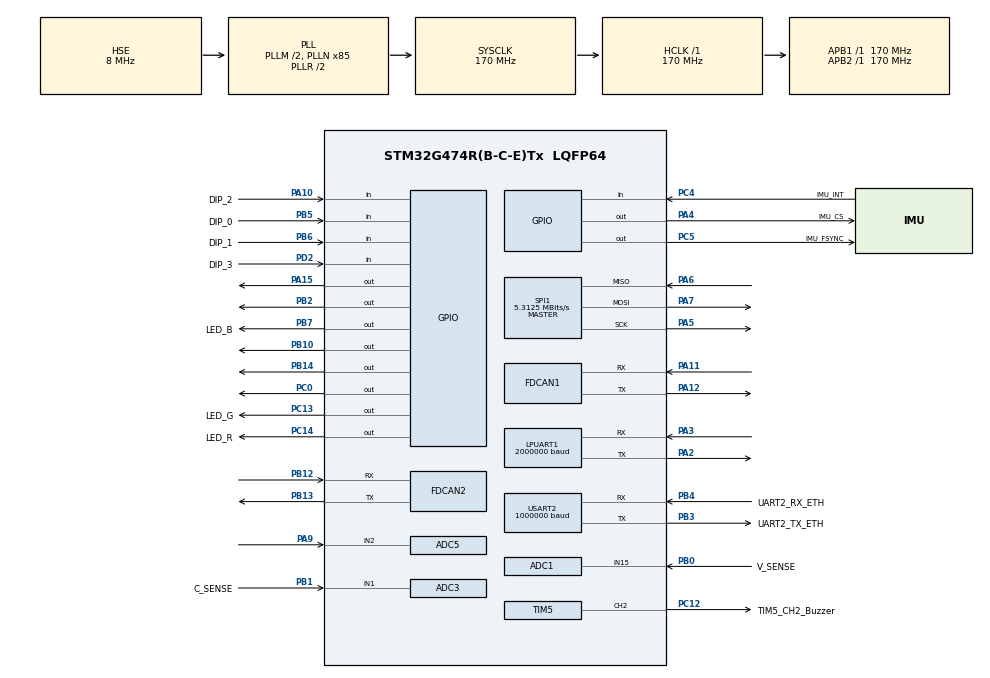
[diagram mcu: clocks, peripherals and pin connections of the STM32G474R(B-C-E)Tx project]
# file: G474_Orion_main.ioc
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ADC1.Channel-0\#ChannelRegularConversion=ADC_CHANNEL_15
ADC1.ContinuousConvMode=ENABLE
ADC1.DMAContinuousRequests=ENABLE
ADC1.NbrOfConversionFlag=1
ADC1.OffsetNumber-0\#ChannelRegularConversion=ADC_OFFSET_NONE
ADC1.OversamplingMode=ENABLE
ADC1.Rank-0\#ChannelRegularConversion=1
ADC1.Ratio=ADC_OVERSAMPLING_RATIO_4
ADC1.RightBitShift=ADC_RIGHTBITSHIFT_2
ADC1.SamplingTime-0\#ChannelRegularConversion=ADC_SAMPLETIME_640CYCLES_5
ADC1.master=1
ADC3.Channel-0\#ChannelRegularConversion=ADC_CHANNEL_1
ADC3.ContinuousConvMode=ENABLE
ADC3.DMAContinuousRequests=ENABLE
ADC3.NbrOfConversion=1
ADC3.NbrOfConversionFlag=1
ADC3.OffsetNumber-0\#ChannelRegularConversion=ADC_OFFSET_NONE
ADC3.OversamplingMode=ENABLE
ADC3.Rank-0\#ChannelRegularConversion=1
ADC3.Ratio=ADC_OVERSAMPLING_RATIO_4
ADC3.RightBitShift=ADC_RIGHTBITSHIFT_2
ADC3.SamplingTime-0\#ChannelRegularConversion=ADC_SAMPLETIME_640CYCLES_5
ADC3.master=1
ADC5.Channel-1\#ChannelRegularConversion=ADC_CHANNEL_2
ADC5.ContinuousConvMode=ENABLE
ADC5.DMAContinuousRequests=ENABLE
ADC5.EOCSelection=ADC_EOC_SINGLE_CONV
ADC5.EnableRegularConversion=ENABLE
ADC5.NbrOfConversionFlag=1
ADC5.OffsetNumber-1\#ChannelRegularConversion=ADC_OFFSET_NONE
ADC5.OversamplingMode=ENABLE
ADC5.Rank-1\#ChannelRegularConversion=1
ADC5.Ratio=ADC_OVERSAMPLING_RATIO_4
ADC5.RightBitShift=ADC_RIGHTBITSHIFT_2
ADC5.SamplingTime-1\#ChannelRegularConversion=ADC_SAMPLETIME_640CYCLES_5
Dma.ADC1.2.Direction=DMA_PERIPH_TO_MEMORY
Dma.ADC1.2.EventEnable=DISABLE
Dma.ADC1.2.Instance=DMA1_Channel5
Dma.ADC1.2.MemDataAlignment=DMA_MDATAALIGN_HALFWORD
Dma.ADC1.2.MemInc=DMA_MINC_ENABLE
Dma.ADC1.2.Mode=DMA_CIRCULAR
Dma.ADC1.2.PeriphDataAlignment=DMA_PDATAALIGN_HALFWORD
Dma.ADC1.2.PeriphInc=DMA_PINC_DISABLE
Dma.ADC1.2.Polarity=HAL_DMAMUX_REQ_GEN_RISING
Dma.ADC1.2.Priority=DMA_PRIORITY_LOW
Dma.ADC1.2.RequestNumber=1
Dma.ADC1.2.SignalID=NONE
Dma.ADC1.2.SyncEnable=DISABLE
Dma.ADC1.2.SyncPolarity=HAL_DMAMUX_SYNC_NO_EVENT
Dma.ADC1.2.SyncRequestNumber=1
Dma.ADC1.2.SyncSignalID=NONE
Dma.ADC3.1.Direction=DMA_PERIPH_TO_MEMORY
Dma.ADC3.1.EventEnable=DISABLE
Dma.ADC3.1.Instance=DMA1_Channel3
Dma.ADC3.1.MemDataAlignment=DMA_MDATAALIGN_HALFWORD
Dma.ADC3.1.MemInc=DMA_MINC_ENABLE
Dma.ADC3.1.Mode=DMA_CIRCULAR
Dma.ADC3.1.PeriphDataAlignment=DMA_PDATAALIGN_HALFWORD
Dma.ADC3.1.PeriphInc=DMA_PINC_DISABLE
Dma.ADC3.1.Polarity=HAL_DMAMUX_REQ_GEN_RISING
Dma.ADC3.1.Priority=DMA_PRIORITY_LOW
Dma.ADC3.1.RequestNumber=1
Dma.ADC3.1.SignalID=NONE
Dma.ADC3.1.SyncEnable=DISABLE
Dma.ADC3.1.SyncPolarity=HAL_DMAMUX_SYNC_NO_EVENT
Dma.ADC3.1.SyncRequestNumber=1
Dma.ADC3.1.SyncSignalID=NONE
Dma.ADC5.0.Direction=DMA_PERIPH_TO_MEMORY
Dma.ADC5.0.EventEnable=DISABLE
Dma.ADC5.0.Instance=DMA1_Channel4
Dma.ADC5.0.MemDataAlignment=DMA_MDATAALIGN_HALFWORD
Dma.ADC5.0.MemInc=DMA_MINC_ENABLE
Dma.ADC5.0.Mode=DMA_CIRCULAR
Dma.ADC5.0.PeriphDataAlignment=DMA_PDATAALIGN_HALFWORD
Dma.ADC5.0.PeriphInc=DMA_PINC_DISABLE
Dma.ADC5.0.Polarity=HAL_DMAMUX_REQ_GEN_RISING
Dma.ADC5.0.Priority=DMA_PRIORITY_LOW
Dma.ADC5.0.RequestNumber=1
Dma.ADC5.0.SignalID=NONE
Dma.ADC5.0.SyncEnable=DISABLE
Dma.ADC5.0.SyncPolarity=HAL_DMAMUX_SYNC_NO_EVENT
Dma.ADC5.0.SyncRequestNumber=1
Dma.ADC5.0.SyncSignalID=NONE
Dma.LPUART1_RX.3.Direction=DMA_PERIPH_TO_MEMORY
Dma.LPUART1_RX.3.EventEnable=DISABLE
Dma.LPUART1_RX.3.Instance=DMA1_Channel6
Dma.LPUART1_RX.3.MemDataAlignment=DMA_MDATAALIGN_BYTE
Dma.LPUART1_RX.3.MemInc=DMA_MINC_ENABLE
Dma.LPUART1_RX.3.Mode=DMA_CIRCULAR
Dma.LPUART1_RX.3.PeriphDataAlignment=DMA_PDATAALIGN_BYTE
Dma.LPUART1_RX.3.PeriphInc=DMA_PINC_DISABLE
Dma.LPUART1_RX.3.Polarity=HAL_DMAMUX_REQ_GEN_RISING
Dma.LPUART1_RX.3.Priority=DMA_PRIORITY_LOW
Dma.LPUART1_RX.3.RequestNumber=1
Dma.LPUART1_RX.3.SignalID=NONE
Dma.LPUART1_RX.3.SyncEnable=DISABLE
Dma.LPUART1_RX.3.SyncPolarity=HAL_DMAMUX_SYNC_NO_EVENT
Dma.LPUART1_RX.3.SyncRequestNumber=1
Dma.LPUART1_RX.3.SyncSignalID=NONE
Dma.LPUART1_TX.4.Direction=DMA_MEMORY_TO_PERIPH
Dma.LPUART1_TX.4.EventEnable=DISABLE
Dma.LPUART1_TX.4.Instance=DMA1_Channel7
Dma.LPUART1_TX.4.MemDataAlignment=DMA_MDATAALIGN_BYTE
Dma.LPUART1_TX.4.MemInc=DMA_MINC_ENABLE
Dma.LPUART1_TX.4.Mode=DMA_NORMAL
Dma.LPUART1_TX.4.PeriphDataAlignment=DMA_PDATAALIGN_BYTE
Dma.LPUART1_TX.4.PeriphInc=DMA_PINC_DISABLE
Dma.LPUART1_TX.4.Polarity=HAL_DMAMUX_REQ_GEN_RISING
Dma.LPUART1_TX.4.Priority=DMA_PRIORITY_LOW
Dma.LPUART1_TX.4.RequestNumber=1
Dma.LPUART1_TX.4.SignalID=NONE
Dma.LPUART1_TX.4.SyncEnable=DISABLE
Dma.LPUART1_TX.4.SyncPolarity=HAL_DMAMUX_SYNC_NO_EVENT
Dma.LPUART1_TX.4.SyncRequestNumber=1
Dma.LPUART1_TX.4.SyncSignalID=NONE
Dma.Request0=ADC5
Dma.Request1=ADC3
Dma.Request2=ADC1
Dma.Request3=LPUART1_RX
Dma.Request4=LPUART1_TX
Dma.Request5=USART2_TX
Dma.USART2_TX.5.Direction=DMA_MEMORY_TO_PERIPH
Dma.USART2_TX.5.EventEnable=DISABLE
Dma.USART2_TX.5.Instance=DMA1_Channel8
Dma.USART2_TX.5.MemDataAlignment=DMA_MDATAALIGN_BYTE
Dma.USART2_TX.5.MemInc=DMA_MINC_ENABLE
Dma.USART2_TX.5.Mode=DMA_NORMAL
Dma.USART2_TX.5.PeriphDataAlignment=DMA_PDATAALIGN_BYTE
Dma.USART2_TX.5.PeriphInc=DMA_PINC_DISABLE
Dma.USART2_TX.5.Polarity=HAL_DMAMUX_REQ_GEN_RISING
Dma.USART2_TX.5.Priority=DMA_PRIORITY_LOW
Dma.USART2_TX.5.RequestNumber=1
Dma.USART2_TX.5.SignalID=NONE
Dma.USART2_TX.5.SyncEnable=DISABLE
Dma.USART2_TX.5.SyncPolarity=HAL_DMAMUX_SYNC_NO_EVENT
Dma.USART2_TX.5.SyncRequestNumber=1
Dma.USART2_TX.5.SyncSignalID=NONE
FDCAN1.AutoRetransmission=ENABLE
FDCAN1.CalculateBaudRateNominal=999999
FDCAN1.CalculateTimeBitNominal=1000
FDCAN1.CalculateTimeQuantumNominal=58.82352941176471
FDCAN1.DataPrescaler=10
FDCAN1.DataTimeSeg1=12
FDCAN1.DataTimeSeg2=2
FDCAN1.NominalPrescaler=10
FDCAN1.NominalTimeSeg1=14
FDCAN1.NominalTimeSeg2=2
FDCAN2.AutoRetransmission=ENABLE
FDCAN2.CalculateBaudRateNominal=999999
FDCAN2.CalculateTimeBitNominal=1000
FDCAN2.CalculateTimeQuantumNominal=58.82352941176471
FDCAN2.DataPrescaler=10
FDCAN2.DataTimeSeg1=12
FDCAN2.DataTimeSeg2=2
FDCAN2.NominalPrescaler=10
FDCAN2.NominalTimeSeg1=14
FDCAN2.NominalTimeSeg2=2
LPUART1.BaudRate=2000000
LPUART1.DMADisableonRxErrorParam=UART_ADVFEATURE_DMA_DISABLEONRXERROR
LPUART1.OverrunDisableParam=UART_ADVFEATURE_OVERRUN_ENABLE
Mcu.Family=STM32G4
Mcu.Name=STM32G474R(B-C-E)Tx
Mcu.Package=LQFP64
NVIC.DMA1_Channel3_IRQn=true\:9\:0\:true\:false\:true\:false\:true\:true
NVIC.DMA1_Channel4_IRQn=true\:10\:0\:true\:false\:true\:false\:true\:true
NVIC.DMA1_Channel5_IRQn=true\:11\:0\:true\:false\:true\:false\:true\:true
NVIC.DMA1_Channel6_IRQn=true\:14\:0\:true\:false\:true\:false\:true\:true
NVIC.DMA1_Channel7_IRQn=true\:15\:0\:true\:false\:true\:false\:true\:true
NVIC.DMA1_Channel8_IRQn=true\:0\:0\:false\:false\:true\:false\:true\:true
NVIC.FDCAN1_IT0_IRQn=true\:3\:0\:true\:false\:true\:true\:true\:true
NVIC.FDCAN1_IT1_IRQn=true\:4\:0\:true\:false\:true\:true\:true\:true
NVIC.FDCAN2_IT0_IRQn=true\:6\:0\:true\:false\:true\:true\:true\:true
NVIC.FDCAN2_IT1_IRQn=true\:7\:0\:true\:false\:true\:true\:true\:true
NVIC.LPUART1_IRQn=true\:13\:0\:true\:false\:true\:true\:true\:true
NVIC.PriorityGroup=NVIC_PRIORITYGROUP_4
NVIC.TIM7_DAC_IRQn=true\:8\:0\:true\:false\:true\:true\:true\:true
NVIC.USART2_IRQn=true\:1\:0\:true\:false\:true\:true\:true\:true
PA10.GPIO_Label=DIP_2
PA10.Signal=GPIO_Input
PA11.Mode=FDCAN_Activate
PA11.Signal=FDCAN1_RX
PA12.Mode=FDCAN_Activate
PA12.Signal=FDCAN1_TX
PA13.Mode=Serial_Wire
PA13.Signal=SYS_JTMS-SWDIO
PA14.Mode=Serial_Wire
PA14.Signal=SYS_JTCK-SWCLK
PA15.Signal=GPIO_Output
PA2.GPIO_PuPd=GPIO_PULLUP
PA2.GPIO_Speed=GPIO_SPEED_FREQ_MEDIUM
PA2.Mode=Asynchronous
PA2.Signal=LPUART1_TX
PA3.GPIO_PuPd=GPIO_PULLUP
PA3.GPIO_Speed=GPIO_SPEED_FREQ_MEDIUM
PA3.Mode=Asynchronous
PA3.Signal=LPUART1_RX
PA4.GPIO_Label=IMU_CS
PA4.Signal=GPIO_Output
PA5.Mode=Full_Duplex_Master
PA5.Signal=SPI1_SCK
PA6.Mode=Full_Duplex_Master
PA6.Signal=SPI1_MISO
PA7.Mode=Full_Duplex_Master
PA7.Signal=SPI1_MOSI
PA9.Mode=IN2-Single-Ended
PA9.Signal=ADC5_IN2
PB0.GPIO_Label=V_SENSE
PB0.Mode=IN15-Single-Ended
PB0.Signal=ADC1_IN15
PB1.GPIO_Label=C_SENSE
PB1.Mode=IN1-Single-Ended
PB1.Signal=ADC3_IN1
PB10.Signal=GPIO_Output
PB12.Mode=FDCAN_Activate
PB12.Signal=FDCAN2_RX
PB13.Mode=FDCAN_Activate
PB13.Signal=FDCAN2_TX
PB14.Signal=GPIO_Output
PB2.Signal=GPIO_Output
PB3.GPIO_Label=UART2_TX_ETH
PB3.GPIO_Speed=GPIO_SPEED_FREQ_MEDIUM
PB3.Mode=Asynchronous
PB3.Signal=USART2_TX
PB4.GPIO_Label=UART2_RX_ETH
PB4.GPIO_PuPd=GPIO_PULLUP
PB4.GPIO_Speed=GPIO_SPEED_FREQ_MEDIUM
PB4.Mode=Asynchronous
PB4.Signal=USART2_RX
PB5.GPIO_Label=DIP_0
PB5.Signal=GPIO_Input
PB6.GPIO_Label=DIP_1
PB6.Signal=GPIO_Input
PB7.GPIO_Label=LED_B
PB7.Signal=GPIO_Output
PC0.Signal=GPIO_Output
PC12.GPIO_Label=TIM5_CH2_Buzzer
PC12.Signal=S_TIM5_CH2
PC13.GPIO_Label=LED_G
PC13.Signal=GPIO_Output
PC14-OSC32_IN.GPIO_Label=LED_R
PC14-OSC32_IN.Signal=GPIO_Output
PC4.GPIO_Label=IMU_INT
PC4.Signal=GPIO_Input
PC5.GPIO_Label=IMU_FSYNC
PC5.Signal=GPIO_Output
PD2.GPIO_Label=DIP_3
PD2.Signal=GPIO_Input
PF0-OSC_IN.Mode=HSE-External-Oscillator
PF0-OSC_IN.Signal=RCC_OSC_IN
PF1-OSC_OUT.Mode=HSE-External-Oscillator
PF1-OSC_OUT.Signal=RCC_OSC_OUT
ProjectManager.HeapSize=0x200
ProjectManager.StackSize=0x400
ProjectManager.TargetToolchain=STM32CubeIDE
RCC.ADC12Freq_Value=170000000
RCC.ADC345Freq_Value=170000000
RCC.AHBFreq_Value=170000000
RCC.APB1Freq_Value=170000000
RCC.APB1TimFreq_Value=170000000
RCC.APB2Freq_Value=170000000
RCC.APB2TimFreq_Value=170000000
RCC.CortexFreq_Value=170000000
RCC.EXTERNAL_CLOCK_VALUE=12288000
RCC.HCLKFreq_Value=170000000
RCC.HSE_VALUE=8000000
RCC.HSI48_VALUE=48000000
RCC.HSI_VALUE=16000000
RCC.LSE_VALUE=32768
RCC.PLLM=RCC_PLLM_DIV2
RCC.PLLN=85
RCC.PLLSourceVirtual=RCC_PLLSOURCE_HSE
RCC.SYSCLKFreq_VALUE=170000000
RCC.SYSCLKSource=RCC_SYSCLKSOURCE_PLLCLK
RCC.USBFreq_Value=170000000
RCC.VCOOutputFreq_Value=340000000
SH.S_TIM5_CH2.0=TIM5_CH2,PWM Generation2 CH2
SPI1.BaudRatePrescaler=SPI_BAUDRATEPRESCALER_32
SPI1.CLKPhase=SPI_PHASE_1EDGE
SPI1.CLKPolarity=SPI_POLARITY_LOW
SPI1.CalculateBaudRate=5.3125 MBits/s
SPI1.DataSize=SPI_DATASIZE_8BIT
SPI1.Direction=SPI_DIRECTION_2LINES
SPI1.FirstBit=SPI_FIRSTBIT_MSB
SPI1.Mode=SPI_MODE_MASTER
SPI1.NSSPMode=SPI_NSS_PULSE_ENABLE
SPI1.VirtualType=VM_MASTER
TIM5.Channel-PWM\ Generation2\ CH2=TIM_CHANNEL_2
TIM5.PeriodNoDither=500
TIM5.Prescaler=170
TIM7.PeriodNoDither=2000
TIM7.Prescaler=170
USART2.BaudRate=1000000
USART2.SwapParam=ADVFEATURE_SWAP_ENABLE
USART2.VirtualMode-Asynchronous=VM_ASYNC
VP_SYS_VS_DBSignals.Mode=DisableDeadBatterySignals
VP_TIM7_VS_ClockSourceINT.Mode=Enable_Timer
board=custom

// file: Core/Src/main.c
/* USER CODE BEGIN Header */
/**
 ******************************************************************************
 * @file           : main.c
 * @brief          : Main program body
 ******************************************************************************
 * @attention
 *
 * <h2><center>&copy; Copyright (c) 2020 STMicroelectronics.
 * All rights reserved.</center></h2>
 *
 * This software component is licensed by ST under BSD 3-Clause license,
 * the "License"; You may not use this file except in compliance with the
 * License. You may obtain a copy of the License at:
 *                        opensource.org/licenses/BSD-3-Clause
 *
 ******************************************************************************
 */
/* USER CODE END Header */
#include "main.h"

#include "adc.h"
#include "dma.h"
#include "fdcan.h"
#include "gpio.h"
#include "spi.h"
#include "tim.h"
#include "usart.h"

/* USER CODE BEGIN Includes */
#include <math.h>
#include <stdarg.h>

#include "management.h"
#include "robot_packet.h"
//

#include "actuator.h"
#include "ai_comm.h"
#include "buzzer_control.h"
#include "can_ibis.h"
#include "control_theta.h"
#include "error.h"
#include "fw_update_gateway.h"
#include "fw_version.h"
#include "icm20602_spi.h"
#include "odom.h"
#include "omni_wheel.h"
#include "ring_buffer.h"
#include "robot_control.h"
#include "state_func.h"
#include "stop_state_control.h"
#include "util.h"

/* Backup register経由で常駐bootloaderへMain更新・pending確定要求を渡す。 */
#define BOOT_REQUEST_UPDATE UINT32_C(0x5557464F)
#define BOOT_REQUEST_CONFIRM UINT32_C(0x4346574F)

/* USER CODE END Includes */

/* USER CODE BEGIN PV */

const fw_version_t g_fw_version __attribute__((section(".fw_version"), used)) = {FW_VERSION_MAGIC, 0U};

/* USER CODE END PV */

void SystemClock_Config(void);
/* USER CODE BEGIN PFP */
void HAL_UART_RxCpltCallback(UART_HandleTypeDef * huart);
void HAL_TIM_PeriodElapsedCallback(TIM_HandleTypeDef * htim);
void HAL_GPIO_EXTI_Callback(uint16_t GPIO_Pin);
void HAL_FDCAN_RxFifo0Callback(FDCAN_HandleTypeDef * hfdcan, uint32_t RxFifo0ITs);
void HAL_FDCAN_TxFifoEmptyCallback(FDCAN_HandleTypeDef * hfdcan);
static void request_main_bootloader(uint32_t request);
static void fw_version_start(void);
static void fw_version_process(void);
static bool fw_version_can_rx(FDCAN_HandleTypeDef * hfdcan, uint32_t identifier, const uint8_t data[8]);
uint8_t getModeSwitch();
bool allEncInitialized();
uint32_t HAL_GetTick(void)
{
  return uwTick;
}

static imu_t imu;
static can_raw_t can_raw;
static target_t target = {.omni_angle_kp = 25, .omni_angle_kd = 2};
static mouse_t mouse;
static omni_t omni;
static output_t output;
static motor_t motor;
static connection_t connection;
static system_t sys;
static integ_control_t integ;
static accel_vector_t acc_vel;
static debug_t debug;
static camera_t camera, camera_buf;

static RobotCommandV2 cmd_v2, cmd_v2_buf;

#define printf_BUF_SIZE 2000
static char printf_buffer[printf_BUF_SIZE];

enum {
  PRINT_IDX_AI_CMD = 0,
  PRINT_IDX_MOTOR,
  PRINT_IDX_DRIBBLER,
  PRINT_IDX_KICKER,
  PRINT_IDX_MOUSE,
  PRINT_IDX_ODOM,
  PRINT_IDX_MOTION,
  PRINT_IDX_VEL,
  PRINT_IDX_LATENCY,
  PRINT_IDX_SYSTEM,
  PRINT_IDX_UART_RAW,
  PRINT_IDX_TUI,
  PRINT_IDX_DRIVE_LOG,
  PRINT_IDX_MAX
};

typedef struct
{
  const char * name;
  uint16_t cycle_hz;
} print_page_config_t;

static const print_page_config_t print_page_config[PRINT_IDX_MAX] = {
  [PRINT_IDX_AI_CMD] = {.name = "AI_CMD", .cycle_hz = PRINT_LOOP_CYCLE},
  [PRINT_IDX_MOTOR] = {.name = "MOTOR", .cycle_hz = PRINT_LOOP_CYCLE},
  [PRINT_IDX_DRIBBLER] = {.name = "DRIBBLER", .cycle_hz = PRINT_LOOP_CYCLE},
  [PRINT_IDX_KICKER] = {.name = "KICKER", .cycle_hz = PRINT_LOOP_CYCLE},
  [PRINT_IDX_MOUSE] = {.name = "MOUSE", .cycle_hz = PRINT_LOOP_CYCLE},
  [PRINT_IDX_ODOM] = {.name = "ODOM", .cycle_hz = PRINT_LOOP_CYCLE},
  [PRINT_IDX_MOTION] = {.name = "MOTION", .cycle_hz = PRINT_LOOP_CYCLE},
  [PRINT_IDX_VEL] = {.name = "VEL", .cycle_hz = PRINT_LOOP_CYCLE},
  [PRINT_IDX_LATENCY] = {.name = "LATENCY", .cycle_hz = PRINT_LOOP_CYCLE},
  [PRINT_IDX_SYSTEM] = {.name = "SYSTEM", .cycle_hz = PRINT_LOOP_CYCLE},
  [PRINT_IDX_UART_RAW] = {.name = "UART", .cycle_hz = PRINT_LOOP_CYCLE},
  [PRINT_IDX_TUI] = {.name = "TUI", .cycle_hz = PRINT_TUI_CYCLE},
  [PRINT_IDX_DRIVE_LOG] = {.name = "DRIVE_LOG", .cycle_hz = 250},
};

// communication with CM4
static uint8_t data_from_cm4[RX_BUF_SIZE_CM4];
static uint8_t uart2_rx_it_buffer = 0, lpuart1_rx_buf = 0;
volatile bool fw_gateway_active = false;
volatile uint8_t fw_gateway_reply[8] = {0};
volatile uint8_t fw_gateway_reply_counter = 0;
static volatile bool fw_gateway_reply_pending = false;
/* COM57から't'を送ると通常テレメトリTXを停止できる。CM4 RXとの競合切り分け用。 */
static volatile bool cm4_telemetry_enabled = true;
static volatile uint32_t cm4_rx_frame_count;
static volatile uint32_t cm4_rx_valid_frame_count;

extern volatile uint32_t uart2_rx_irq_count;
extern volatile uint32_t uart2_rx_data_irq_count;
extern volatile uint32_t uart2_rx_byte_count;
extern volatile uint32_t uart2_rx_ore_count;
extern volatile uint32_t uart2_rx_fe_count;
extern volatile uint32_t uart2_rx_ne_count;
extern volatile uint32_t uart2_rx_pe_count;
extern volatile uint32_t uart2_rx_max_drain;

typedef struct __attribute__((packed)) {
  uint32_t build_id;
  uint32_t image_crc32c;
} fw_version_entry_t;

typedef struct __attribute__((packed)) {
  uint8_t magic[4];
  uint8_t format;
  uint8_t active_slot;
  uint8_t present_mask;
  uint8_t valid_mask;
  fw_version_entry_t entry[6];
  uint32_t crc32c;
} fw_version_response_t;

_Static_assert(sizeof(fw_version_response_t) == 60U, "FW version response size changed");

static fw_version_response_t fw_version_response;
static volatile bool fw_version_collecting = false;
static volatile uint32_t fw_version_deadline = 0U;
static volatile uint32_t fw_version_next_request = 0U;

static uint32_t fw_version_crc32c(const void * source, uint32_t length)
{
  const uint8_t * data = source;
  uint32_t crc = UINT32_C(0xFFFFFFFF);
  for (uint32_t index = 0U; index < length; index++) {
    crc ^= data[index];
    for (uint32_t bit = 0U; bit < 8U; bit++) crc = (crc >> 1U) ^ ((crc & 1U) ? UINT32_C(0x82F63B78) : 0U);
  }
  return ~crc;
}

static void fw_version_load_main_slot(uint32_t slot)
{
  const uint32_t app_base = slot == 0U ? UINT32_C(0x08008000) : UINT32_C(0x08040000);
  const uint32_t metadata_base = slot == 0U ? UINT32_C(0x08078000) : UINT32_C(0x08078800);
  const fw_version_t * version = (const fw_version_t *)(app_base + UINT32_C(0x400));
  const uint32_t * metadata = (const uint32_t *)metadata_base;
  if (version->magic == FW_VERSION_MAGIC) {
    fw_version_response.present_mask |= (uint8_t)(1U << slot);
    fw_version_response.entry[slot].build_id = version->build_id;
  }
  if (metadata[0] == UINT32_C(0x3157464F) && metadata[3] == 4U && version->magic == FW_VERSION_MAGIC) {
    fw_version_response.valid_mask |= (uint8_t)(1U << slot);
    fw_version_response.entry[slot].image_crc32c = metadata[7];
  }
}

static void fw_version_request_missing(void)
{
  uint8_t request[8] = {0U};
  if ((fw_version_response.present_mask & (1U << 2U)) == 0U) {
    request[0] = 4U;
    can1_send(0x611, request);
  }
  if ((fw_version_response.present_mask & (1U << 3U)) == 0U) {
    request[0] = 16U;
    can1_send(0x611, request);
  }
  if ((fw_version_response.present_mask & (1U << 4U)) == 0U) {
    request[0] = 17U;
    can2_send(0x611, request);
  }
  if ((fw_version_response.present_mask & (1U << 5U)) == 0U) {
    request[0] = 100U;
    can1_send(0x611, request);
    can2_send(0x611, request);
  }
}

static void fw_version_start(void)
{
  memset(&fw_version_response, 0, sizeof(fw_version_response));
  memcpy(fw_version_response.magic, "FWVR", 4U);
  fw_version_response.format = 1U;
  fw_version_response.active_slot = SCB->VTOR >= UINT32_C(0x08040000) ? 1U : 0U;
  fw_version_load_main_slot(0U);
  fw_version_load_main_slot(1U);
  const uint32_t now = HAL_GetTick();
  fw_version_collecting = true;
  fw_version_deadline = now + 250U;
  fw_version_next_request = now + 40U;
  fw_version_request_missing();
}

static bool fw_version_can_rx(FDCAN_HandleTypeDef * hfdcan, uint32_t identifier, const uint8_t data[8])
{
  uint32_t index;
  if (!fw_version_collecting) return false;
  if (hfdcan->Instance == FDCAN1 && identifier == 0x664U) index = 2U;
  else if (hfdcan->Instance == FDCAN1 && identifier == 0x670U) index = 3U;
  else if (hfdcan->Instance == FDCAN2 && identifier == 0x671U) index = 4U;
  else if ((hfdcan->Instance == FDCAN1 || hfdcan->Instance == FDCAN2) && identifier == 0x6C4U) index = 5U;
  else return false;
  memcpy(&fw_version_response.entry[index], data, 8U);
  fw_version_response.present_mask |= (uint8_t)(1U << index);
  if (fw_version_response.entry[index].build_id != 0U) fw_version_response.valid_mask |= (uint8_t)(1U << index);
  return true;
}

static void fw_version_process(void)
{
  if (!fw_version_collecting) return;
  const uint32_t now = HAL_GetTick();
  if ((int32_t)(now - fw_version_deadline) < 0) {
    if ((int32_t)(now - fw_version_next_request) >= 0) {
      fw_version_next_request = now + 40U;
      fw_version_request_missing();
    }
    return;
  }
  if (huart2.gState != HAL_UART_STATE_READY) return;
  fw_version_collecting = false;
  fw_version_response.crc32c = fw_version_crc32c(&fw_version_response, sizeof(fw_version_response) - sizeof(uint32_t));
  (void)HAL_UART_Transmit(&huart2, (uint8_t *)&fw_version_response, sizeof(fw_version_response), 20U);
}

static void fw_gateway_send_uart_reply(void)
{
  if (!fw_gateway_reply_pending || huart2.gState != HAL_UART_STATE_READY) return;

  uint8_t frame[16] = {'F', 'W', 'R', 'P'};
  __disable_irq();
  memcpy(&frame[4], (const void *)fw_gateway_reply, 8U);
  frame[12] = fw_gateway_reply_counter;
  fw_gateway_reply_pending = false;
  __enable_irq();
  frame[13] = 0U;
  for (uint32_t i = 0; i < 13U; i++) frame[13] = (uint8_t)(frame[13] + frame[i]);
  frame[14] = '\r'; frame[15] = '\n';
  if (HAL_UART_Transmit(&huart2, frame, sizeof(frame), 10U) != HAL_OK) {
    fw_gateway_reply_pending = true;
  }
}

/* USER CODE END PFP */

/* USER CODE BEGIN 0 */

void __io_putchar(uint8_t ch)
{
  HAL_UART_Transmit(&hlpuart1, &ch, 1, 1);
}

void p(const char * format, ...)
{
  va_list args;
  va_start(args, format);
  if (strlen(printf_buffer) > printf_BUF_SIZE * 0.9) {
    vsprintf(printf_buffer, "\e[1m\e[31m\n\n\n\nUART BUFFER OVERRUN ERROR\n\n\n\n", args);
    return;
  }
  vsprintf(printf_buffer + strlen(printf_buffer), format, args);
  va_end(args);
}

void setTextRed()
{
  p("\e[31m");
}
void setTextYellow()
{
  p("\e[33m");
}
void setTextGreen()
{
  p("\e[32m");
}
//void setTextBlue() { p("\e[34m"); } //見づらいので非推奨
void setTextMagenta()
{
  p("\e[35m");
}
void setTextCyan()
{
  p("\e[36m");
}
void setTextNormal()
{
  p("\e[0m");
}

void setTextBold()
{
  p("\e[1m");
}

// たまにLPUARTの割り込みが停止するので自動復帰
void checkAndRestartLPUART_IT(void)
{
  if ((hlpuart1.Instance->CR1 & USART_CR1_RXNEIE) == 0) {
    HAL_UART_Receive_IT(&hlpuart1, &lpuart1_rx_buf, 1);
  }
}

static void setPrintPage(int32_t index)
{
  while (index < 0) {
    index += PRINT_IDX_MAX;
  }
  debug.print_idx = index % PRINT_IDX_MAX;
}

static bool copyDriveLogSample(drive_log_sample_t * destination)
{
  for (int retry = 0; retry < 3; retry++) {
    const uint32_t sequence_before = debug.drive_log_sequence;
    if ((sequence_before & 1U) != 0U) {
      continue;
    }

    *destination = debug.drive_log;
    __DMB();
    if (sequence_before == debug.drive_log_sequence) {
      return true;
    }
  }
  return false;
}

/* USER CODE END 0 */

int main(void)
{

  /* MCU Configuration--------------------------------------------------------*/

  /* Reset of all peripherals, Initializes the Flash interface and the Systick. */
  HAL_Init();

  /* Configure the system clock */
  SystemClock_Config();

  /* Initialize all configured peripherals */
  MX_GPIO_Init();
  MX_DMA_Init();
  MX_FDCAN1_Init();
  MX_LPUART1_UART_Init();
  MX_USART2_UART_Init();
  MX_SPI1_Init();
  MX_TIM5_Init();
  MX_TIM7_Init();
  MX_ADC5_Init();
  MX_ADC3_Init();
  MX_FDCAN2_Init();
  MX_ADC1_Init();
  /* USER CODE BEGIN 2 */

  integ.odom_log[0] = initRingBuffer(SPEED_LOG_BUF_SIZE);
  integ.odom_log[1] = initRingBuffer(SPEED_LOG_BUF_SIZE);
  omni.local_speed_log[0] = initRingBuffer(SPEED_MOVING_AVERAGE_FILTER_BUF_SIZE);
  omni.local_speed_log[1] = initRingBuffer(SPEED_MOVING_AVERAGE_FILTER_BUF_SIZE);
  omni.local_speed_log[2] = initRingBuffer(SPEED_MOVING_AVERAGE_FILTER_BUF_SIZE);

  sys.kick_state = 0;
  HAL_TIM_PWM_Start(&htim5, TIM_CHANNEL_2);

  actuator_buzzer_frq(1046, 50);  //C5
  actuator_buzzer_frq(1174, 50);  //D5
  actuator_buzzer_frq(1318, 50);  //E5
  actuator_buzzer_frq(1396, 50);  //F5

  setbuf(stdin, NULL);
  setbuf(stdout, NULL);
  setbuf(stderr, NULL);

  /* MX_USART2_UART_Init()で設定したRX FIFOを維持したまま受信割り込みを開始する。 */
  /* DMA完了IRQによるDMAT/TCIEの更新を古い値で上書きしない。 */
  ATOMIC_SET_BIT(huart2.Instance->CR3, USART_CR3_EIE);
  ATOMIC_SET_BIT(huart2.Instance->CR1, USART_CR1_RXNEIE_RXFNEIE);

  HAL_UART_Init(&hlpuart1);
  HAL_UART_Receive_IT(&hlpuart1, &lpuart1_rx_buf, 1);

  printf("orion main start [%s] [%s]\r\n", __DATE__, __TIME__);

  HAL_ADC_Start_DMA(&hadc5, &sys.sw_adc_raw, 1);

  setHighUartRxLED();
  setHighInterruptLED();
  setHighEventLED();
  ICM20602_init();
  ICM20602_init();
  ICM20602_IMU_calibration2();
  ICM20602_clearAngle();

  printf("\n\rcomplete imu init\r\n");
  // CANより先にIMUのキャリブレーションする

  printf("\n\rstart can1\r\n");
  can1_init_ibis(&hfdcan1);

  printf("\n\rstart can2\r\n");
  can2_init_ibis(&hfdcan2);

  actuatorPower_ONOFF(0);
  HAL_Delay(20);

  actuator_motor_fr(0.0);
  actuator_motor_br(0.0);
  actuator_motor_bl(0.0);
  actuator_motor_fl(0.0);
  actuator_motor_drv(0.0);

  kicker_charge_start();
  actuator_kicker_cmd_voltage(0.0);
  actuator_power_param(1, 15.0);  // min voltage
  actuator_power_param(2, 35.0);  // max voltage
  actuator_power_param(3, 50.0);  // max can_raw.current
  actuator_power_param(4, 90.0);  // max temp(fet)
  actuator_power_param(5, 90.0);  // max temp(solenoid)

  setLowUartRxLED();
  setLowEventLED();
  setLowInterruptLED();
  actuatorPower_ONOFF(1);

  actuator_buzzer_frq(1046, 50);  //C5
  actuator_buzzer_frq(1174, 50);  //D5
  actuator_buzzer_frq(1046, 50);  //C5
  actuator_buzzer_frq(1174, 50);  //D5
  actuator_buzzer_frq(1318, 50);  //E5
  actuator_buzzer_frq(1396, 50);  //F5

  actuatorPower_ONOFF(1);

  sys.system_time_ms = 1000;  //
  requestStop(&sys, 1000);    // !!注意!! TIM7の割り込みがはじまってから1000ms間停止
  connection.already_connected_ai = false;
  HAL_Delay(100);
  HAL_TIM_Base_Start_IT(&htim7);
  // TIM interrupt is TIM7 only.

  HAL_Delay(500);
  debug.print_idx = PRINT_IDX_ODOM;

  char error_str[100] = {0};

  /* USER CODE END 2 */

  /* Infinite loop */
  while (1) {

    /* USER CODE BEGIN 3 */

    fw_gateway_send_uart_reply();
    fw_update_gateway_process();
    fw_version_process();

    debug.sys_mnt.main_loop_cnt++;
    if (debug.print_flag /* && fabsf(omni.local_odom_speed_mvf[0]) > 0.01*/) {
      debug.print_flag = false;

      // 文字列初期化
      printf_buffer[0] = 0;
      if (debug.print_idx != PRINT_IDX_DRIVE_LOG) {
        p("\e[0m");  //初期化
      }

      // IDXリスト表示
      static uint8_t pre_print_idx = 0;
      if (pre_print_idx != debug.print_idx) {
        pre_print_idx = debug.print_idx;
        for (int i = 0; i < PRINT_IDX_MAX; i++) {
          if (debug.print_idx == i) {
            setTextGreen();
            setTextBold();
          } else {
            setTextNormal();
          }
          p(" %s ", print_page_config[i].name);
        }
        setTextNormal();
        p("\n");
        if (debug.print_idx == PRINT_IDX_DRIVE_LOG) {
          p("DRV_HEADER,t_ms,cmd_r,cmd_th,tar_vx,tar_vy,now_vx,now_vy,acc_x,acc_y,yaw,yaw_rate,yaw_tar,yaw_drag,angle_clear_count,angle_clear_active,rotation_angle_error,rotation_clear_step");
          for (int i = 0; i < 4; i++) {
            p(",tar%d,real%d,current%d_A,angle_err%d,rps_err%d,kp%d,kd%d,ff%d,yaw_out%d,out%d,age%d_ms", i, i, i, i, i, i, i, i, i, i, i);
          }
          p(",real_rf_lf,real_rb_lb,out_rf_lf,out_rb_lb\n");
        }
      }

      if (debug.print_idx != PRINT_IDX_DRIVE_LOG) {
        // 電圧表示
        if (isLowVoltage(&can_raw)) {
          setTextYellow();
        }
        p("Batt=%3.1f ", getBatteryRemain(&can_raw));
        setTextNormal();

        if (sys.main_mode == MAIN_MODE_ERROR) {
          setTextRed();
          convertErrorDataToStr(sys.current_error.id, sys.current_error.info, error_str);
          p("Err %s %+5.2f ", error_str, sys.current_error.value);
          setTextNormal();
        }
        if (isStopRequested(&sys)) {
          setTextYellow();
        }
      }

      debug.print_cycle = print_page_config[debug.print_idx].cycle_hz;
      switch (debug.print_idx) {
        case PRINT_IDX_AI_CMD:
          // 通信接続状態表示
          //p("itr %4d %8d %8d ", debug.sys_mnt.uart_rx_itr_cnt, connection.latest_cm4_cmd_update_time, connection.latest_ai_cmd_update_time);

          p("CMD ");
          p("STP%d ", cmd_v2.stop_emergency);

          if (connection.connected_ai) {
            setTextGreen();
          } else if (connection.connected_cm4) {
            setTextYellow();
          } else {
            setTextRed();
          }
          // ai_cmd_rx_frqは実装されていない
          p("Ck%3d,%3.0fHz\e[37m ", cmd_v2.check_counter, connection.ai_cmd_rx_frq);

          if (cmd_v2.is_vision_available && cmd_v2.elapsed_time_ms_since_last_vision < 200) {
            setTextGreen();
          } else if (!cmd_v2.stop_emergency) {
            setTextYellow();
          } else {
            setTextRed();
          }
          p("VisionX %+6.2f Y %+6.2f ", cmd_v2.vision_global_pos[0], cmd_v2.vision_global_pos[1]);
          p("theta %+6.1f ", cmd_v2.vision_global_theta * 180 / M_PI);
          p("elt %4d ", cmd_v2.elapsed_time_ms_since_last_vision);
          setTextNormal();
          p("Ltcy %3d ", cmd_v2.latency_time_ms);

          p("TarTheta %+6.2f ", cmd_v2.target_global_theta);
          p("Lmt: Spd %4.2f Omg %4.1f Acc %4.2f / ", cmd_v2.linear_velocity_limit, cmd_v2.angular_velocity_limit, cmd_v2.acceleration_limit);

          p("dri %+4.2f ", cmd_v2.dribble_power);

          if (cmd_v2.enable_chip) {
            setTextCyan();
            p("chip %3.2f ", cmd_v2.kick_power);
          } else {
            setTextMagenta();
            p("stlt %3.2f ", cmd_v2.kick_power);
          }

          setTextNormal();

          /*********************************************************************************************** */
          if (cmd_v2.control_mode == POLAR_VELOCITY_TARGET_MODE) {
            p("PolarVel ");
            p("VelR %+6.2f T %+6.2f ", cmd_v2.mode_args.polar_velocity.target_global_velocity_r, cmd_v2.mode_args.polar_velocity.target_global_velocity_theta);
            break;
          } else {
            p("Unknown Mode ");
          }

          p("TX %3d RX %3d /50ms ", debug.sys_mnt.robot_info_tx_cnt, debug.sys_mnt.ai_cmd_rx_cnt);
          debug.sys_mnt.robot_info_tx_cnt = 0;
          debug.sys_mnt.ai_cmd_rx_cnt = 0;

          /*********************************************************************************************** */

          break;
        case PRINT_IDX_MOTOR:  //Motor

          p("MOTOR ");
          float spin_total = can_raw.motor_feedback[0] + can_raw.motor_feedback[1] + can_raw.motor_feedback[2] + can_raw.motor_feedback[3];
          p("Spd %+6.1f %+6.1f %+6.1f %+6.1f total %+6.1f/ ", can_raw.motor_feedback[0], can_raw.motor_feedback[1], can_raw.motor_feedback[2], can_raw.motor_feedback[3], spin_total);
          //p("Spd M0=%+6.1f M1=%+6.1f M2=%+6.1f M3=%+6.1f / ", omni.travel_distance[0], omni.travel_distance[1], omni.travel_distance[2], omni.travel_distance[3]);
          p("PwV %5.1f %5.1f %5.1f %5.1f / ", can_raw.power_voltage[0], can_raw.power_voltage[1], can_raw.power_voltage[2], can_raw.power_voltage[3]);
          p("Im %+5.2f %+5.2f %+5.2f %+5.2f / ", can_raw.current[0], can_raw.current[1], can_raw.current[2], can_raw.current[3]);
          const int MOTOR_OVER_HEAT_WARN_THRESH = 60;
          p("Temp ");
          for (int i = 0; i < 4; i++) {
            if (can_raw.temp_motor[i] > MOTOR_OVER_HEAT_WARN_THRESH) {
              setTextYellow();
            } else {
              setTextNormal();
            }
            p("M%d %3.0f ", i, can_raw.temp_motor[i]);
          }
          setTextNormal();
          p("EncNzAvgDeg ");
          for (int i = 0; i < 4; i++) {
            p("%5.3f ", motor.enc_noise_avg_rad[i]);
          }
          p("Max ");
          for (int i = 0; i < 4; i++) {
            p("%5.3f ", motor.enc_noise_max_rad[i]);
          }
          for (int i = 0; i < 4; i++) {
            if (can_raw.temp_driver[i] > MOTOR_OVER_HEAT_WARN_THRESH) {
              setTextYellow();
            } else {
              setTextNormal();
            }
            p("D%d %3.0f ", i, can_raw.temp_driver[i]);
          }
          setTextNormal();
          p("Rps ");
          for (int i = 0; i < 4; i++) {
            p("%4.2f ", can_raw.motor_param_rps[i]);
          }
          break;

        case PRINT_IDX_DRIBBLER:  // Dribblerテスト
          p("DRIBBLER ");
          p("Batt(Sub) %3.1f / ", can_raw.power_voltage[4]);
          p("ball_sensor %d %d / ESC Spd %+5.0f / ", can_raw.ball_detection[0], can_raw.ball_detection[1], can_raw.motor_feedback[4]);
          //p("local_vision x=%3d y=%3d radius=%3d FPS=%3d ", ai_cmd.ball_local_x, ai_cmd.ball_local_y, ai_cmd.ball_local_radius, ai_cmd.ball_local_FPS);
          p("omni.gos %+6.3f ", omni.global_odom_speed[0]);
          break;

        case PRINT_IDX_KICKER:  // Kicker Test
          p("KICKER ");
          p("Cnt %3d ", sys.kick_state);
          p("Batt(Pw) %3.1f ", can_raw.power_voltage[5]);
          if (can_raw.power_voltage[6] > 100) {
            setTextYellow();
          } else {
            setTextNormal();
          }
          p("Cap=%3.0f ", can_raw.power_voltage[6]);
          setTextNormal();
          p("BattC %+6.1f Batt(Sub) %3.1f / ", can_raw.current[4], can_raw.power_voltage[4]);
          const int KICKER_OVER_HEAT_WARN_THRESH = 70;  // power側でエラーは80度
          if (can_raw.temp_fet > KICKER_OVER_HEAT_WARN_THRESH || can_raw.temp_coil[0] > KICKER_OVER_HEAT_WARN_THRESH || can_raw.temp_coil[1] > KICKER_OVER_HEAT_WARN_THRESH) {
            setTextYellow();
          } else {
            setTextNormal();
          }
          p("FET=%5.1f L1=%5.1f L2=%5.1f / ", can_raw.temp_fet, can_raw.temp_coil[0], can_raw.temp_coil[1]);
          setTextNormal();
          p("ball_sensor %d %d / ESC Spd %+5.0f ", can_raw.ball_detection[0], can_raw.ball_detection[1], can_raw.motor_feedback[4]);

          break;

        case PRINT_IDX_MOUSE:  // Mouse odom
          p("MOUSE ");
          p("%d / enc all%d %d %d %d %d / ", can_raw.rx_stat.mouse_flag, allEncInitialized(&can_raw), can_raw.rx_stat.enc_flag[0], can_raw.rx_stat.enc_flag[1], can_raw.rx_stat.enc_flag[2],
            can_raw.rx_stat.enc_flag[3]);
          //p("raw_odom X %+8.3f Y %+8.3f ", mouse.raw_odom[0] * 1000, mouse.raw_odom[1] * 1000);
          //p("mouse floor X %+8.3f Y %+8.3f ", mouse.floor_odom[0] * 1000, mouse.floor_odom[1] * 1000);
          p("omni-odom X %+8.1f ,Y %+8.1f ", omni.odom[0] * 1000, omni.odom[1] * 1000);
          p("mouse X %+8.2f Y %+8.2f ", mouse.odom[0] * 1000, mouse.odom[1] * 1000);
          p("Error X %+8.2f Y %+8.2f ", (mouse.odom[0] - omni.odom[0]) * 1000, (mouse.odom[1] - omni.odom[1]) * 1000);
          p("diff X %+8.2f Y %+8.2f ", mouse.raw_diff[0] * 1000, mouse.raw_diff[1] * 1000);
          p("MsVel X %+8.2f Y %+8.2f ", mouse.global_vel[0], mouse.global_vel[1]);
          //p("mouseRaw X %+8.1f Y %+8.1f ", mouse.raw[0], mouse.raw[1]);
          if (mouse.quality < 100) {
            setTextRed();
          } else if (mouse.quality < 150) {
            setTextYellow();
          } else {
            setTextGreen();
          }
          p("/ raw X %+4d Y %+4d Q %6d", mouse.raw[0], mouse.raw[1], mouse.quality);

          break;

        case PRINT_IDX_ODOM:
          p("ODOM ");

          if (cmd_v2.is_vision_available && cmd_v2.elapsed_time_ms_since_last_vision < 200) {
            setTextGreen();
          } else if (!cmd_v2.stop_emergency) {
            setTextYellow();
          } else {
            setTextRed();
          }

          p("VisionX %+6.2f Y %+6.2f ", cmd_v2.vision_global_pos[0], cmd_v2.vision_global_pos[1]);
          p("theta %+6.1f ", cmd_v2.vision_global_theta * 180 / M_PI);
          p("elt %4d ", cmd_v2.elapsed_time_ms_since_last_vision);
          setTextNormal();

          p("imu %+5.1f ", imu.yaw_deg);
          p("Dt %4d LtCy %4d ", connection.ai_cmd_delta_time, integ.latency_cycle);
          p("integ.govd %+7.2f %+7.2f ", integ.global_odom_vision_diff[0] * 1000, integ.global_odom_vision_diff[1] * 1000);
          p("integ.vbp %+5.2f %+5.2f ", integ.vision_based_position[0], integ.vision_based_position[1]);
          p("omni.gos X %+8.1f ,Y %+8.1f. ", omni.global_odom_speed[0] * 1000, omni.global_odom_speed[1] * 1000);
          p("omgD %+6.3f ", getAngleDiff(imu.yaw_rad, imu.pre_yaw_rad) * 4000);
          p("omg %+6.2f ", output.omega);
          break;

        case PRINT_IDX_MOTION:
          p("MOTION ");
          p("theta %+6.1f ", imu.yaw_deg);

          //p("omg %+3.0f out %+5.2f, %+5.2f ", output.omega, output.velocity[0], output.velocity[1]);
          //p("ENC angle %+6.3f %+6.3f %+6.3f %+6.3f ", motor.angle_rad[0], motor.angle_rad[1], motor.angle_rad[2], motor.angle_rad[3]);
          //p("odomL X %+8.3f, Y %+8.3f, ", omni.odom[0], omni.odom[1]);
          //p("omni-GV X %+8.1f ,Y %+8.1f. ", omni.global_odom_speed[0] * 1000, omni.global_odom_speed[1] * 1000);
          if (cmd_v2.is_vision_available) {
            setTextCyan();
          } else {
            setTextYellow();
          }
          p("VisionX %+6.2f Y %+6.2f ", cmd_v2.vision_global_pos[0], cmd_v2.vision_global_pos[1]);
          //p("integ.govd %+7.2f %+7.2f ", integ.global_odom_vision_diff[0] * 1000, integ.global_odom_vision_diff[1] * 1000);
          //p("integ.vbp %+5.2f %+5.2f ", integ.vision_based_position[0], integ.vision_based_position[1]);
          p("diffG %+6.3f %+6.3f ", integ.position_diff[0], integ.position_diff[1]);
          //p("dist %+6.3f ", target.pos_ctrl.target_pos_dist_scalar);
          //p("Global-VO %+6.3f Y %+6.3f ", target.global_vel[0], target.global_vel[1]);
          //p("angle %+5.2f ", target.pos_ctrl.target_vel_angle);

          //p("GlobalVel %+6.3f Y %+6.3f ", target.pos_ctrl.global_odom_speed[0], target.pos_ctrl.global_odom_speed[1]);
          /*p("tarScV %+5.2f ", target.pos_ctrl.target_scalar_vel);
          if (target.pos_ctrl.target_scalar_vel > target.pos_ctrl.current_speed_crd[0]) {
            setTextCyan();
          } else {
            setTextMagenta();
          }
          p("CrSpdCrd %+5.2f,%+5.2f ", target.pos_ctrl.current_speed_crd[0], target.pos_ctrl.current_speed_crd[1]);
          setTextNormal();
          p("accCrd X %+6.2f, Y %+6.2f ", target.pos_ctrl.target_crd_acc[0], target.pos_ctrl.target_crd_acc[1]);
          p("accGl X %+6.2f, Y %+6.2f ", target.pos_ctrl.global_acc[0], target.pos_ctrl.global_acc[1]);
          p("%d ", target.pos_ctrl.to_stop_mode_flag);
          */
          //p("local-VO %+6.3f Y %+6.3f ", output.velocity[0], output.velocity[1]);

          //p("MsVel X %+8.4f Y %+8.4f ", mouse.global_vel[0], mouse.global_vel[1]);
          //p("AI X %+4.1f Y %+4.1f ", ai_cmd.local_target_speed[0], ai_cmd.local_target_speed[1]);
          //p("integ-diff %+6.3f %+6.3f ", integ.local_target_diff[0], integ.local_target_diff[1]);
          //p("tar-pos X %+8.1f, Y %+8.1f ", target.global_vel_now[0], target.global_vel_now[1]);
          //p("cmd-vel %+5.2f, %+5.2f, ", target.global_vel[0], target.global_vel[1]);
          //p("vel-now %+6.3f, %+6.3f, ", target.local_vel_now[0], target.local_vel_now[1]);
          //p("vel-diff X %+8.2f, Y %+8.2f, ", acc_vel.vel_error_xy[0] * 1000, acc_vel.vel_error_xy[1] * 1000);
          //p("rad %+8.2f, scalar %+8.2f, ", acc_vel.vel_error_rad * 180 / M_PI, acc_vel.vel_error_scalar * 1000);
          //p("out-vel %+5.1f, %+5.1f ", output.velocity[0], output.velocity[1]);
          //p("acc sca %7.4f rad %5.2f ", acc_vel.vel_error_scalar, acc_vel.vel_error_rad);
          //p("real-vel X %+7.2f, Y %+7.2f, 2 %+7.2f,", omni.local_odom_speed_mvf[0], omni.local_odom_speed_mvf[1], omni.local_odom_speed_mvf[2]);

          p("TarTheta %+6.2f ", cmd_v2.target_global_theta);

          const float DEAD_ZONE_RADIAN = 5 * M_PI / 180;

          float angle_diff = getAngleDiff(cmd_v2.target_global_theta, imu.yaw_rad);

          p("Diff %+6.2f ", angle_diff);

          if (fabsf(angle_diff) < DEAD_ZONE_RADIAN) {
            angle_diff = 0;
          } else {
            if (angle_diff > 0) {
              angle_diff -= DEAD_ZONE_RADIAN;
            } else {
              angle_diff += DEAD_ZONE_RADIAN;
            }
          }
          p("Diff %+6.2f ", angle_diff);

          //float temp_tar_rps = angle_diff * DIFF_TO_RPS_GAIN;
          float temp_tar_rps = sqrtf(fabsf(2 * angle_diff * 50));
          p("Temp %+6.2f ", temp_tar_rps);

          temp_tar_rps = copysignf(temp_tar_rps, angle_diff);

          p("Temp %+6.2f ", temp_tar_rps);
          p("YawTar %+6.2f ", target.yaw_rps);
          //p("vel-diff %+8.3f, %+8.3f, ", target.local_vel_now[0] - omni.local_odom_speed_mvf[0], target.local_vel_now[1] - omni.local_odom_speed_mvf[1]);

          break;

        case PRINT_IDX_VEL:
          p("VEL ");
          p("theta %+6.1f ", imu.yaw_deg);
          //p("rawVel X %+8.3f, Y %+8.3f, ", omni.local_raw_odom_vel[0], omni.local_raw_odom_vel[1]);
          //p("rawGbVel X %+8.3f, Y %+8.3f ", omni.global_raw_odom_vel[0], omni.global_raw_odom_vel[1]);
          //p("rawGbOdom X %+8.3f, Y %+8.3f, ", omni.global_raw_odom[0], omni.global_raw_odom[1]);
          //p("odom X %+8.3f, Y %+8.3f, ", omni.odom[0], omni.odom[1]);
          //p("tar X %+8.3f, Y %+8.3f, ", target.global_pos[0], target.global_pos[1]);
          //p("offset X %+8.3f, Y %+8.3f, ", omni.offset_dist[0], omni.offset_dist[1]);
          //p("odomSpd X %+8.3f, Y %+8.3f, ", omni.global_odom_speed[0], omni.global_odom_speed[1]);
          //p("real-vel X %+8.3f, Y %+8.3f, X2 %+8.3f,", omni.local_odom_speed_mvf[0], omni.local_odom_speed_mvf[1], omni.local_odom_speed_mvf[2]);
          //p("out-vel X %+5.1f, Y %+5.1f W %+5.1f ", output.velocity[0], output.velocity[1], output.omega);
          //p("M0 %+5.2f M1 %+5.2f M2 %+5.2f M3 %+5.2f ", output.motor_voltage[0], output.motor_voltage[1], output.motor_voltage[2], output.motor_voltage[3]);
          //p("Err X%+5.1f Y%+5.1f Sc%+5.1f ", acc_vel.vel_error_xy[0], acc_vel.vel_error_xy[1], acc_vel.vel_error_scalar);
          p("accLc X %+6.1f, Y %+6.1f, B %+6.3f, S %+6.1f, ", acc_vel.accel[0], acc_vel.accel[1], acc_vel.accel_boost_gain, acc_vel.accel_scalar);
          //p("TarLocal %+5.1f %+5.1f TarGlobalN %+5.1f %+5.1f TarLocalN %+5.1f %+5.1f ", target.local_vel[0], target.local_vel[1], target.global_vel_now[0], target.global_vel_now[1],target.local_vel_now[0], target.local_vel_now[1]);
          //p("Diff X %+5.3f, Y %+5.3f, ", omni.robot_pos_diff[0], omni.robot_pos_diff[1]);  // x150は出力ゲイン
          //p("FF-N %+5.1f FF-T %+5.1f ", target.local_vel_ff_factor[0], target.local_vel_ff_factor[1]);
          //p("vel-now %+6.3f, %+6.3f, ", target.local_vel_now[0], target.local_vel_now[1]);
          //p("real-vel X %+7.2f, Y %+7.2f, 2 %+7.2f,", omni.local_odom_speed_mvf[0], omni.local_odom_speed_mvf[1], omni.local_odom_speed_mvf[2]);
          p("KP %+4.1f KD %+4.1f ", target.omni_angle_kp, target.omni_angle_kd);
          p("Tar");
          for (int i = 0; i < 4; i++) {
            p("%+6.1f ", target.omni_angle[i].current_tar_rps);
          }
          p("Real");
          for (int i = 0; i < 4; i++) {
            p("%+6.1f ", target.omni_angle[i].real_rps);
          }
          /*           p("Diff");
          for (int i = 0; i < 4; i++) {
            p("%+6.1f ", target.omni_angle[i].diff * 100);
          } */
          p("Vout");
          for (int i = 0; i < 4; i++) {
            p("%+6.1f ", output.motor_voltage[i]);
          }
          //p("/ M0 Acc %+6.3f ", target.omni_angle[0].tar_aps_acc);
          //p("V %+6.2f ", output.motor_voltage[0]);
          float temp = 0;
          for (int i = 0; i < 4; i++) {
            temp += target.omni_angle[i].diff;
          }
          p("total %+6.2f spin %+6.2f drag %+6.2f ", temp, target.yaw_rps, target.yaw_rps_drag);
          break;

        case PRINT_IDX_LATENCY:
          p("LATENCY ");
          p("setting : %3d / ", cmd_v2.latency_time_ms);
          p("EN %d cnt %4d target %+5.2f diff %+5.2f / ", debug.latency_check.enabled, debug.latency_check.seq_cnt, debug.latency_check.rotation_target_theta,
            getAngleDiff(debug.latency_check.rotation_target_theta, imu.yaw_rad));
          if (camera.is_connected == 0) {
            setTextNormal();
          } else {
            setTextGreen();
          }
          p("CAM ");
          p("Cn %d %6d ", camera.is_connected, sys.system_time_ms - camera.latest_local_cam_update_time);
          p("x %+4d y%+4d rad%4d fps%3d ", camera.pos_xy[0], camera.pos_xy[1], camera.radius, camera.fps);

          break;

        case PRINT_IDX_SYSTEM:
          p("SYSTEM TIME ");
          p("NOW ");
          for (int i = 0; i < 7; i++) {
            if (debug.sys_mnt.tim_cnt_max[i] < debug.sys_mnt.tim_cnt_now[i]) {
              debug.sys_mnt.tim_cnt_max[i] = debug.sys_mnt.tim_cnt_now[i];
            }
            p("%4.1f%% ", (float)debug.sys_mnt.tim_cnt_now[i] * 100 / 2000);
          }
          p(" / MAX ");
          for (int i = 0; i < 7; i++) {
            p("%4.1f%% ", (float)debug.sys_mnt.tim_cnt_max[i] * 100 / 2000);
          }
          p("TO ");
          p("PW%4d ", can_raw.rx_stat.timeout_cnt[BOARD_ID_POWER]);
          p("RD%4d ", can_raw.rx_stat.timeout_cnt[BOARD_ID_MOTOR_RIGHT]);
          p("LD%4d ", can_raw.rx_stat.timeout_cnt[BOARD_ID_MOTOR_LEFT]);
          p("SB%4d ", can_raw.rx_stat.timeout_cnt[BOARD_ID_SUB]);
          uint32_t can_motor_samples = can_tx_debug.motor_call_samples;
          uint32_t can_motor_avg_us = can_motor_samples == 0 ? 0 : can_tx_debug.motor_call_delta_sum_us / can_motor_samples;
          p("CANd L%u A%lu M%u N%lu OK%lu/%lu E%lu/%lu B%lu/%lu D%lu/%lu ", can_tx_debug.motor_call_delta_last_us, can_motor_avg_us, can_tx_debug.motor_call_delta_max_us,
            can_motor_samples, can_tx_debug.tx_add_ok[0], can_tx_debug.tx_add_ok[1], can_tx_debug.tx_add_error[0], can_tx_debug.tx_add_error[1], can_tx_debug.sw_buffered[0],
            can_tx_debug.sw_buffered[1], can_tx_debug.sw_dropped[0], can_tx_debug.sw_dropped[1]);
          p("MotorV ");
          for (int i = 0; i < 4; i++) {
            p("%+6.2f ", output.motor_voltage[i]);
          }
          p("SW ADC %3.2fV ", (float)3.3 * sys.sw_adc_raw / 4096);
          convertErrorDataToStr(sys.latest_error.id, sys.latest_error.info, error_str);
          p("ErrLatest %s %+5.2f Resume %2d ", error_str, sys.latest_error.value, sys.current_error.resume_cnt);
          break;

        case PRINT_IDX_UART_RAW:
          //dumpAIFeedback();
          p("UART RAW ");
          setTextNormal();
          for (int i = 0; i < 64; i++) {
            p("0x%02x ", data_from_cm4[i]);
          }
          setTextCyan();
          for (int i = 64; i < 64 + 8; i++) {
            p("0x%02x ", data_from_cm4[i]);
          }
          setTextMagenta();
          p(" ck 0x%2x , error %4d", connection.check_cnt, connection.check_sum_error_cnt);
          p(" RX age%4lu TX%d irq%lu rxirq%lu byte%lu frame%lu valid%lu max%lu PE%lu FE%lu NE%lu ORE%lu", (unsigned long)(sys.system_time_ms - connection.latest_cm4_cmd_update_time),
            cm4_telemetry_enabled, (unsigned long)uart2_rx_irq_count, (unsigned long)uart2_rx_data_irq_count, (unsigned long)uart2_rx_byte_count,
            (unsigned long)cm4_rx_frame_count, (unsigned long)cm4_rx_valid_frame_count, (unsigned long)uart2_rx_max_drain,
            (unsigned long)uart2_rx_pe_count, (unsigned long)uart2_rx_fe_count, (unsigned long)uart2_rx_ne_count, (unsigned long)uart2_rx_ore_count);
          break;

        case PRINT_IDX_DRIVE_LOG: {
          drive_log_sample_t log;
          if (!copyDriveLogSample(&log)) {
            p("DRV_RETRY\n");
            break;
          }

          p("DRV,%lu,%+.4f,%+.4f,%+.4f,%+.4f,%+.4f,%+.4f,%+.3f,%+.3f,%+.5f,%+.4f,%+.4f,%+.3f,%u,%u,%+.6f,%+.6f", log.time_ms, log.cmd_velocity_r,
            log.cmd_velocity_theta, log.target_local_vel[0], log.target_local_vel[1], log.target_local_vel_now[0], log.target_local_vel_now[1], log.accel[0], log.accel[1], log.yaw_rad,
            log.yaw_rate, log.target_yaw_rps, log.yaw_rps_drag, log.angle_clear_stable_count, log.angle_clear_active, log.rotation_angle_error, log.rotation_clear_step);
          for (int i = 0; i < 4; i++) {
            p(",%+.3f,%+.3f,%+.1f,%+.5f,%+.3f,%+.3f,%+.3f,%+.3f,%+.3f,%+.3f,%lu", log.target_rps[i], log.real_rps[i], log.motor_current_a[i], log.angle_diff[i],
              log.rps_diff[i], log.kp_output[i], log.kd_output[i], log.ff_output[i], log.yaw_output[i], log.motor_output[i], log.motor_rx_age_ms[i]);
          }
          p(",%+.3f,%+.3f,%+.3f,%+.3f", log.real_rps[0] + log.real_rps[3], log.real_rps[1] + log.real_rps[2], log.motor_output[0] + log.motor_output[3],
            log.motor_output[1] + log.motor_output[2]);
          break;
        }

        case PRINT_IDX_TUI:
          p("hogehoge1\n");
          p("hogehoge2\n");
          p("hogehoge3\n");
          p("\e[4A");
          break;
        default:
          debug.print_idx = 0;
          break;
      }

      if (debug.print_idx != PRINT_IDX_DRIVE_LOG) {
        if (debug.sys_mnt.main_loop_cnt < 100000 || debug.print_idx == PRINT_IDX_SYSTEM) {
          p("loop %6d", debug.sys_mnt.main_loop_cnt / 10);
        }
        if (debug.sys_mnt.timer_itr_exit_cnt > 1500) {  // 2ms cycleのとき、max 2000cnt
          p("cnt %4d", debug.sys_mnt.timer_itr_exit_cnt);
        }
      }
      p("\n");
      HAL_UART_Transmit_DMA(&hlpuart1, (uint8_t *)printf_buffer, strlen(printf_buffer));

      debug.sys_mnt.main_loop_cnt = 0;
      debug.sys_mnt.uart_rx_itr_cnt = 0;

      // whileで毎回呼ぶ必要はないのでprintに併せて呼ぶ
      checkAndRestartLPUART_IT();
    }
  }
  /* USER CODE END 3 */
}

void SystemClock_Config(void)
{
  RCC_OscInitTypeDef RCC_OscInitStruct = {0};
  RCC_ClkInitTypeDef RCC_ClkInitStruct = {0};

  /** Configure the main internal regulator output voltage
  */
  HAL_PWREx_ControlVoltageScaling(PWR_REGULATOR_VOLTAGE_SCALE1_BOOST);

  /** Initializes the RCC Oscillators according to the specified parameters
  * in the RCC_OscInitTypeDef structure.
  */
  RCC_OscInitStruct.OscillatorType = RCC_OSCILLATORTYPE_HSE;
  RCC_OscInitStruct.HSEState = RCC_HSE_ON;
  RCC_OscInitStruct.PLL.PLLState = RCC_PLL_ON;
  RCC_OscInitStruct.PLL.PLLSource = RCC_PLLSOURCE_HSE;
  RCC_OscInitStruct.PLL.PLLM = RCC_PLLM_DIV2;
  RCC_OscInitStruct.PLL.PLLN = 85;
  RCC_OscInitStruct.PLL.PLLP = RCC_PLLP_DIV2;
  RCC_OscInitStruct.PLL.PLLQ = RCC_PLLQ_DIV2;
  RCC_OscInitStruct.PLL.PLLR = RCC_PLLR_DIV2;
  if (HAL_RCC_OscConfig(&RCC_OscInitStruct) != HAL_OK) {
    Error_Handler();
  }

  /** Initializes the CPU, AHB and APB buses clocks
  */
  RCC_ClkInitStruct.ClockType = RCC_CLOCKTYPE_HCLK | RCC_CLOCKTYPE_SYSCLK | RCC_CLOCKTYPE_PCLK1 | RCC_CLOCKTYPE_PCLK2;
  RCC_ClkInitStruct.SYSCLKSource = RCC_SYSCLKSOURCE_PLLCLK;
  RCC_ClkInitStruct.AHBCLKDivider = RCC_SYSCLK_DIV1;
  RCC_ClkInitStruct.APB1CLKDivider = RCC_HCLK_DIV1;
  RCC_ClkInitStruct.APB2CLKDivider = RCC_HCLK_DIV1;

  if (HAL_RCC_ClockConfig(&RCC_ClkInitStruct, FLASH_LATENCY_4) != HAL_OK) {
    Error_Handler();
  }
}

/* USER CODE BEGIN 4 */

// 必要なデータが揃ったらodom系をゼロで初期化
void resetOdomAtEncInitialized()
{
  static bool initialized_flag = false;

  if (initialized_flag == false && allEncInitialized(&can_raw)) {
    for (int i = 0; i < 2; i++) {
      omni.odom[i] = 0;
      omni.pre_odom[i] = 0;
      mouse.floor_odom[i] = 0;
      omni.local_raw_odom_vel[i] = 0;
    }
    for (int i = 0; i < 4; i++) {
      motor.pre_angle_rad[i] = motor.angle_rad[i];
    }
    initialized_flag = true;
  }
}

void HAL_FDCAN_RxFifo0Callback(FDCAN_HandleTypeDef * hfdcan, uint32_t RxFifo0ITs)
{
  uint8_t RxData[CAN_RX_DATA_SIZE];
  FDCAN_RxHeaderTypeDef RxHeader;

  while ((RxFifo0ITs & FDCAN_IT_RX_FIFO0_NEW_MESSAGE) != RESET && HAL_FDCAN_GetRxFifoFillLevel(hfdcan, FDCAN_RX_FIFO0) > 0U) {
    if (HAL_FDCAN_GetRxMessage(hfdcan, FDCAN_RX_FIFO0, &RxHeader, RxData) != HAL_OK) {
      Error_Handler();
    }

    if (fw_update_gateway_can_rx(hfdcan, RxHeader.Identifier, RxData)) {
      continue;
    }
    if (fw_version_can_rx(hfdcan, RxHeader.Identifier, RxData)) {
      continue;
    }
    if (fw_gateway_active && hfdcan->Instance == FDCAN1 && RxHeader.Identifier == 0x634U) {
      memcpy((void *)fw_gateway_reply, RxData, 8U);
      fw_gateway_reply_counter++;
      fw_gateway_reply_pending = true;
      return;
    }
    parseCanCmd(RxHeader.Identifier, RxData, &can_raw, &sys, &motor, &mouse);
    // 関数のネストを浅くするためにparseCanCmd()の中から移動
    if (RxHeader.Identifier == 0x241) {
      mouseOdometryUpdate(&mouse, &imu);
    }
  }
}

void HAL_FDCAN_TxFifoEmptyCallback(FDCAN_HandleTypeDef * hfdcan)
{
  canTxEmptyInterrupt(hfdcan);
}

void HAL_TIM_PeriodElapsedCallback(TIM_HandleTypeDef * htim)
{
  sys.system_time_ms += (1000 / MAIN_LOOP_CYCLE);
  if (fw_gateway_active) {
    maintaskStop(&output);
    actuator_buzzer_off();
    return;
  }
  // TIM interrupt is TIM7 only.

  debug.sys_mnt.tim_cnt_now[0] = htim7.Instance->CNT;  // パフォーマンス計測用

  // sys.main_mode設定
  static uint8_t sw_mode;
  sw_mode = getModeSwitch();

  // 関数化したほうがええかも
  if (connection.updated_flag) {
    connection.updated_flag = false;
    memcpy(&cmd_v2, &cmd_v2_buf, sizeof(RobotCommandV2));
  }
  commStateCheck(&connection, &sys, &cmd_v2);

  if (connection.camera_updated_flag) {
    connection.camera_updated_flag = false;
    memcpy(&camera, &camera_buf, sizeof(camera_t));

    // need to set : is_detected,is_connected,latest_local_cam_update_time
    camera.latest_local_cam_update_time = sys.system_time_ms;
    camera.is_connected = true;
    if (camera.radius != 0) {
      camera.is_detected = true;
    } else {
      camera.is_detected = false;
    }
  }
  if (sys.system_time_ms - camera.latest_local_cam_update_time > 200) {
    camera.is_detected = false;
    camera.is_connected = false;
  }

  canRxTimeoutCntCycle(&can_raw);

  sys.can_timeout = canRxTimeoutDetection(&can_raw);
  sys.enc_initialized = allEncInitialized(&can_raw);

  stopStateControl(&sys, sw_mode);

  // 以後sys.main_modeによる動作切り替え

  debug.sys_mnt.tim_cnt_now[1] = htim7.Instance->CNT;  // パフォーマンス計測用

  yawFilter(&sys, &debug, &imu, &cmd_v2, &connection);
  omniOdometryUpdate(&motor, &omni, &imu);  // 250us
  inntegOdomUpdate(&cmd_v2, &omni, &integ, &connection, &imu, &sys);

  resetOdomAtEncInitialized();

  debug.sys_mnt.tim_cnt_now[2] = htim7.Instance->CNT;  // パフォーマンス計測用

  debug.sys_mnt.tim_cnt_now[3] = htim7.Instance->CNT;  // パフォーマンス計測用

  switch (sys.main_mode) {
    case MAIN_MODE_FULL_AI_CONTROL:  // ローカル統合制御あり
    case MAIN_MODE_MANUAL_CONTROL:   // ローカル統合制御なし
      maintaskRun(&sys, &cmd_v2, &imu, &acc_vel, &integ, &target, &omni, &mouse, &debug, &output, &can_raw, &motor, &camera);
      break;
    case MAIN_MODE_CMD_DEBUG_MODE:  // local test mode, Visionなし前提。
                                    // 相補フィルタなし、
      maintaskRun(&sys, &cmd_v2, &imu, &acc_vel, &integ, &target, &omni, &mouse, &debug, &output, &can_raw, &motor, &camera);
      break;

    case MAIN_MODE_MOTOR_TEST:  // motor test
      motorTest(&sys, &output, &omni);
      break;

    case MAIN_MODE_DRIBBLER_TEST:  // dribble test
      dribblerTest(&sys, &output, &can_raw);
      break;

    case MAIN_MODE_KICKER_AUTO_TEST:  // kicker test (auto)
      kickerTest(&sys, &can_raw, false, &output);
      break;

    case MAIN_MODE_KICKER_MANUAL:  // kicker test (manual)
      kickerTest(&sys, &can_raw, true, &output);
      break;

    case MAIN_MODE_LATENCY_CHECK:
      latencyCheck(&sys, &debug, &cmd_v2, &output, &imu);
      break;

    case MAIN_MODE_MOTOR_CALIBRATION:
      motorCalibration(&sys);
      break;

    case MAIN_MODE_ERROR:  // error
      manualPowerReset(&sys);
      maintaskStop(&output);
      sendCanError();
      break;

    default:
      maintaskStop(&output);
      break;
  }

  debug.sys_mnt.tim_cnt_now[4] = htim7.Instance->CNT;  // パフォーマンス計測用
  buzzerControl(&can_raw, &sys, &connection, &cmd_v2);

  debug.sys_mnt.tim_cnt_now[5] = htim7.Instance->CNT;  // パフォーマンス計測用

  // interrupt : 500Hz
  static uint16_t comm_cycle_cnt;
  static uint16_t robot_info_send_cnt;
  uint16_t print_cycle_div = MAIN_LOOP_CYCLE / debug.print_cycle;
  bool print_timing = (comm_cycle_cnt % print_cycle_div) == 0;
  uint16_t robot_info_send_target_cnt = ((comm_cycle_cnt + 1) * ROBOT_INFO_CYCLE) / MAIN_LOOP_CYCLE;

  if (print_timing) {

    debug.print_flag = true;

    if (sys.main_mode == MAIN_MODE_ERROR) {
      actuatorPower_ONOFF(0);
    } else {
      actuatorPower_ONOFF(1);
    }

    toggleInterruptLED();
  }
  /* FW更新中はOFW2応答と通常テレメトリのUSART2送信競合を防ぐ。 */
  if (cm4_telemetry_enabled && !fw_gateway_active && !print_timing && robot_info_send_cnt < robot_info_send_target_cnt) {
    sendRobotInfo(&can_raw, &sys, &imu, &omni, &mouse, &cmd_v2, &connection, &integ, &output, &target);
    robot_info_send_cnt++;
  }

  comm_cycle_cnt++;
  if (comm_cycle_cnt >= MAIN_LOOP_CYCLE) {
    comm_cycle_cnt = 0;
    robot_info_send_cnt = 0;
  }
  debug.sys_mnt.tim_cnt_now[6] = htim7.Instance->CNT;  // パフォーマンス計測用
  debug.sys_mnt.timer_itr_exit_cnt = htim7.Instance->CNT;
}

uint8_t getModeSwitch()
{
  return 15 - (HAL_GPIO_ReadPin(DIP_0_GPIO_Port, DIP_0_Pin) + (HAL_GPIO_ReadPin(DIP_1_GPIO_Port, DIP_1_Pin) << 1) + (HAL_GPIO_ReadPin(DIP_2_GPIO_Port, DIP_2_Pin) << 3) +
               (HAL_GPIO_ReadPin(DIP_3_GPIO_Port, DIP_3_Pin) << 2));
}

void cm4_uart_rx_byte(uint8_t value)
{
  /* USART2 IRQでFIFOから取り出したbyteを既存のCM4パーサへ渡す。 */
  uart2_rx_it_buffer = value;
  HAL_UART_RxCpltCallback(&huart2);
}

void HAL_UART_RxCpltCallback(UART_HandleTypeDef * huart)
{
  static int32_t uart_rx_cmd_idx = -1;
  uint8_t rx_data_tmp;
  RobotCommandSerializedV2 cmd_data_v2;

  debug.sys_mnt.uart_rx_itr_cnt++;

  if (huart->Instance == USART2) {
    rx_data_tmp = uart2_rx_it_buffer;
    /* RX割り込みは起動時に有効化済み。IRQ側でFIFOを直接drainするため再armしない。 */

    if (fw_gateway_active) {
      fw_update_gateway_uart_rx_byte(rx_data_tmp);
      return;
    }

    if (uart_rx_cmd_idx >= 0 && uart_rx_cmd_idx < RX_BUF_SIZE_CM4) {
      data_from_cm4[uart_rx_cmd_idx] = rx_data_tmp;
    }

    // look up header byte
    if (uart_rx_cmd_idx == -1 && rx_data_tmp == 254) {
      data_from_cm4[0] = rx_data_tmp;
      uart_rx_cmd_idx++;
    }

    // data byte
    if (uart_rx_cmd_idx != -1 && uart_rx_cmd_idx < RX_BUF_SIZE_CM4) {
      uart_rx_cmd_idx++;
    }

    // end
    if (uart_rx_cmd_idx == RX_BUF_SIZE_CM4) {
      const bool checksum_ok = checkCM4CmdCheckSun(&connection, data_from_cm4);
      cm4_rx_frame_count++;
      if (checksum_ok) {
        cm4_rx_valid_frame_count++;
      }
      // UARTバスを送受信で同時に使えないので、受信完了してから送信開始
      //sendRobotInfo(&can_raw, &sys, &imu, &omni, &mouse, &cmd_v2, &connection, &integ, &output, &target);
      debug.sys_mnt.robot_info_tx_cnt++;
      uart_rx_cmd_idx = -1;
      if (checksum_ok && memcmp(&data_from_cm4[1], "FWVR", 4U) == 0) {
        fw_version_start();
      } else if (checksum_ok && memcmp(&data_from_cm4[1], "FWUP", 4U) == 0) {
        const uint8_t gateway_command = data_from_cm4[5];
        if (gateway_command == 1U) {
          fw_gateway_active = true;
          fw_update_gateway_start(data_from_cm4[17]);
          HAL_TIM_PWM_Stop(&htim5, TIM_CHANNEL_2);
          actuator_buzzer_off();
          const uint8_t reply[8] = {0xF1U, 0U, 0U, 0U, 0U, 0U, 0U, data_from_cm4[17]};
          memcpy((void *)fw_gateway_reply, reply, sizeof(reply));
          fw_gateway_reply_counter++;
          fw_gateway_reply_pending = true;
        } else if (gateway_command == 2U && fw_gateway_active) {
          const uint32_t can_id = (uint32_t)data_from_cm4[6] | ((uint32_t)data_from_cm4[7] << 8U);
          can1_send((int)can_id, &data_from_cm4[8]);
        } else if (gateway_command == 3U) {
          fw_gateway_active = false;
          NVIC_SystemReset();
        } else if (gateway_command == 4U) {
          request_main_bootloader(BOOT_REQUEST_UPDATE);
        } else if (gateway_command == 5U) {
          request_main_bootloader(BOOT_REQUEST_CONFIRM);
        }
      } else if (checksum_ok) {
        memcpy(&cmd_data_v2, data_from_cm4, sizeof(cmd_data_v2));
        cmd_v2_buf = RobotCommandSerializedV2_deserialize(&cmd_data_v2);
        updateCM4CmdTimeStamp(&connection, &sys);
        debug.sys_mnt.ai_cmd_rx_cnt++;
        // check updated
        camera_buf = parseCameraPacket(&(data_from_cm4[64]));
        if (camera_buf.fps != 0) {
          connection.camera_updated_flag = true;
        }
      }
    }
  }

  if (huart->Instance == hlpuart1.Instance) {
    switch (lpuart1_rx_buf) {
      case 'q':
        target.omni_angle_kp *= 1.1;
        break;
      case 'a':
        target.omni_angle_kp /= 1.1;
        break;
      case 'w':
        target.omni_angle_kd *= 1.1;
        break;
      case 's':
        target.omni_angle_kd /= 1.1;
        break;
      case 'g':
        setPrintPage(PRINT_IDX_DRIVE_LOG);
        break;
      case 't':
        cm4_telemetry_enabled = !cm4_telemetry_enabled;
        break;
      case '0':
      case '1':
      case '2':
      case '3':
      case '4':
      case '5':
      case '6':
      case '7':
      case '8':
      case '9':
        setPrintPage(lpuart1_rx_buf - '0');
        break;
      case 0x7f:  // del
        setPrintPage(PRINT_IDX_AI_CMD);
        break;
      case '\n':
      case '\r':
        setPrintPage(debug.print_idx + 1);
        break;
      default:
        setPrintPage(debug.print_idx - 1);
        break;
    }
    HAL_UART_Receive_IT(&hlpuart1, &lpuart1_rx_buf, 1);
  }
}

/* USER CODE END 4 */

void Error_Handler(void)
{
  /* USER CODE BEGIN Error_Handler_Debug */
  /* User can add his own implementation to report the HAL error return state */
  while (1) {
    setHighEventLED();
    actuator_buzzer(200, 200);
    // NVIC_sysReset();
  }
  /* USER CODE END Error_Handler_Debug */
}

static void request_main_bootloader(uint32_t request)
{
  HAL_TIM_PWM_Stop(&htim5, TIM_CHANNEL_2);
  actuator_buzzer_off();
  RCC->APB1ENR1 |= RCC_APB1ENR1_PWREN | RCC_APB1ENR1_RTCAPBEN;
  (void)RCC->APB1ENR1;
  PWR->CR1 |= PWR_CR1_DBP;
  while ((PWR->CR1 & PWR_CR1_DBP) == 0U) {}
  TAMP->BKP1R = SCB->VTOR >= UINT32_C(0x08040000) ? 1U : 0U;
  TAMP->BKP0R = request;
  __DSB();
  NVIC_SystemReset();
}
